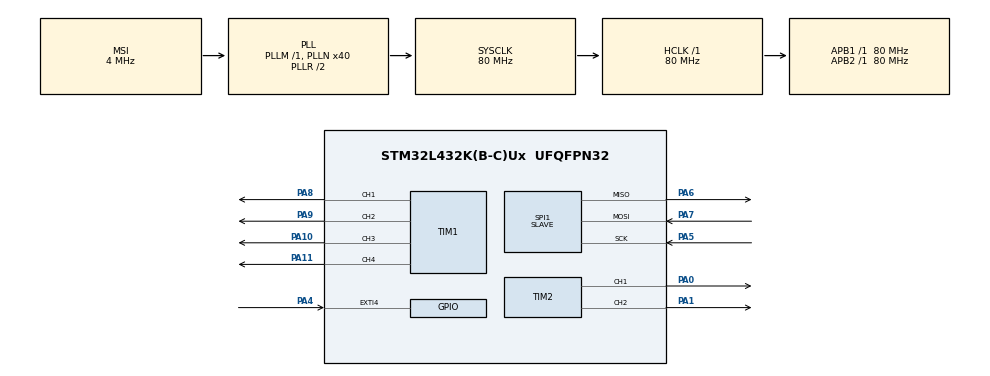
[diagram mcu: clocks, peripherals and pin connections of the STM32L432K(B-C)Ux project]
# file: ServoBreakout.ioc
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Dma.Request0=SPI1_RX
Dma.Request1=SPI1_TX
Dma.SPI1_RX.0.Direction=DMA_PERIPH_TO_MEMORY
Dma.SPI1_RX.0.Instance=DMA1_Channel2
Dma.SPI1_RX.0.MemDataAlignment=DMA_MDATAALIGN_BYTE
Dma.SPI1_RX.0.MemInc=DMA_MINC_ENABLE
Dma.SPI1_RX.0.Mode=DMA_NORMAL
Dma.SPI1_RX.0.PeriphDataAlignment=DMA_PDATAALIGN_BYTE
Dma.SPI1_RX.0.PeriphInc=DMA_PINC_DISABLE
Dma.SPI1_RX.0.Priority=DMA_PRIORITY_LOW
Dma.SPI1_TX.1.Direction=DMA_MEMORY_TO_PERIPH
Dma.SPI1_TX.1.Instance=DMA1_Channel3
Dma.SPI1_TX.1.MemDataAlignment=DMA_MDATAALIGN_BYTE
Dma.SPI1_TX.1.MemInc=DMA_MINC_ENABLE
Dma.SPI1_TX.1.Mode=DMA_NORMAL
Dma.SPI1_TX.1.PeriphDataAlignment=DMA_PDATAALIGN_BYTE
Dma.SPI1_TX.1.PeriphInc=DMA_PINC_DISABLE
Dma.SPI1_TX.1.Priority=DMA_PRIORITY_LOW
Mcu.Family=STM32L4
Mcu.Name=STM32L432K(B-C)Ux
Mcu.Package=UFQFPN32
NVIC.DMA1_Channel2_IRQn=true\:0\:0\:false\:true\:true\:1\:false
NVIC.DMA1_Channel3_IRQn=true\:0\:0\:false\:true\:true\:2\:false
NVIC.EXTI4_IRQn=true\:0\:0\:false\:false\:true\:true
NVIC.PriorityGroup=NVIC_PRIORITYGROUP_4
PA0.GPIO_Speed=GPIO_SPEED_FREQ_VERY_HIGH
PA0.Signal=S_TIM2_CH1
PA1.GPIO_Speed=GPIO_SPEED_FREQ_VERY_HIGH
PA1.Signal=S_TIM2_CH2
PA10.GPIO_Speed=GPIO_SPEED_FREQ_VERY_HIGH
PA10.Signal=S_TIM1_CH3
PA11.GPIO_Speed=GPIO_SPEED_FREQ_VERY_HIGH
PA11.Signal=S_TIM1_CH4
PA4.GPIO_PuPd=GPIO_PULLDOWN
PA4.Signal=GPXTI4
PA5.Mode=Full_Duplex_Slave
PA5.Signal=SPI1_SCK
PA6.Mode=Full_Duplex_Slave
PA6.Signal=SPI1_MISO
PA7.Mode=Full_Duplex_Slave
PA7.Signal=SPI1_MOSI
PA8.GPIO_Speed=GPIO_SPEED_FREQ_VERY_HIGH
PA8.Signal=S_TIM1_CH1
PA9.GPIO_Speed=GPIO_SPEED_FREQ_VERY_HIGH
PA9.Signal=S_TIM1_CH2
ProjectManager.HeapSize=0x200
ProjectManager.StackSize=0x400
ProjectManager.TargetToolchain=SW4STM32
RCC.AHBFreq_Value=80000000
RCC.APB1Freq_Value=80000000
RCC.APB1TimFreq_Value=80000000
RCC.APB2Freq_Value=80000000
RCC.APB2TimFreq_Value=80000000
RCC.CortexFreq_Value=80000000
RCC.HCLKFreq_Value=80000000
RCC.HSE_VALUE=8000000
RCC.HSI48_VALUE=48000000
RCC.HSI_VALUE=16000000
RCC.LSE_VALUE=32768
RCC.MSI_VALUE=4000000
RCC.PLLN=40
RCC.SYSCLKFreq_VALUE=80000000
RCC.SYSCLKSource=RCC_SYSCLKSOURCE_PLLCLK
RCC.VCOOutputFreq_Value=160000000
SH.S_TIM1_CH1.0=TIM1_CH1,PWM Generation1 CH1
SH.S_TIM1_CH2.0=TIM1_CH2,PWM Generation2 CH2
SH.S_TIM1_CH3.0=TIM1_CH3,PWM Generation3 CH3
SH.S_TIM1_CH4.0=TIM1_CH4,PWM Generation4 CH4
SH.S_TIM2_CH1.0=TIM2_CH1,PWM Generation1 CH1
SH.S_TIM2_CH2.0=TIM2_CH2,PWM Generation2 CH2
SPI1.Direction=SPI_DIRECTION_2LINES
SPI1.Mode=SPI_MODE_SLAVE
SPI1.VirtualType=VM_SLAVE
TIM1.Channel-PWM\ Generation1\ CH1=TIM_CHANNEL_1
TIM1.Channel-PWM\ Generation2\ CH2=TIM_CHANNEL_2
TIM1.Channel-PWM\ Generation3\ CH3=TIM_CHANNEL_3
TIM1.Channel-PWM\ Generation4\ CH4=TIM_CHANNEL_4
TIM2.Channel-PWM\ Generation1\ CH1=TIM_CHANNEL_1
TIM2.Channel-PWM\ Generation2\ CH2=TIM_CHANNEL_2
board=custom

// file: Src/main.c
/**
 ******************************************************************************
 * @file           : main.c
 * @brief          : Main program body
 ******************************************************************************
 ** This notice applies to any and all portions of this file
 * that are not between comment pairs USER CODE BEGIN and
 * USER CODE END. Other portions of this file, whether
 * inserted by the user or by software development tools
 * are owned by their respective copyright owners.
 *
 * COPYRIGHT(c) 2019 STMicroelectronics
 *
 * Redistribution and use in source and binary forms, with or without modification,
 * are permitted provided that the following conditions are met:
 *   1. Redistributions of source code must retain the above copyright notice,
 *      this list of conditions and the following disclaimer.
 *   2. Redistributions in binary form must reproduce the above copyright notice,
 *      this list of conditions and the following disclaimer in the documentation
 *      and/or other materials provided with the distribution.
 *   3. Neither the name of STMicroelectronics nor the names of its contributors
 *      may be used to endorse or promote products derived from this software
 *      without specific prior written permission.
 *
 * THIS SOFTWARE IS PROVIDED BY THE COPYRIGHT HOLDERS AND CONTRIBUTORS "AS IS"
 * AND ANY EXPRESS OR IMPLIED WARRANTIES, INCLUDING, BUT NOT LIMITED TO, THE
 * IMPLIED WARRANTIES OF MERCHANTABILITY AND FITNESS FOR A PARTICULAR PURPOSE ARE
 * DISCLAIMED. IN NO EVENT SHALL THE COPYRIGHT HOLDER OR CONTRIBUTORS BE LIABLE
 * FOR ANY DIRECT, INDIRECT, INCIDENTAL, SPECIAL, EXEMPLARY, OR CONSEQUENTIAL
 * DAMAGES (INCLUDING, BUT NOT LIMITED TO, PROCUREMENT OF SUBSTITUTE GOODS OR
 * SERVICES; LOSS OF USE, DATA, OR PROFITS; OR BUSINESS INTERRUPTION) HOWEVER
 * CAUSED AND ON ANY THEORY OF LIABILITY, WHETHER IN CONTRACT, STRICT LIABILITY,
 * OR TORT (INCLUDING NEGLIGENCE OR OTHERWISE) ARISING IN ANY WAY OUT OF THE USE
 * OF THIS SOFTWARE, EVEN IF ADVISED OF THE POSSIBILITY OF SUCH DAMAGE.
 *
 ******************************************************************************
 */
#include "main.h"
#include "stm32l4xx_hal.h"

SPI_HandleTypeDef hspi1;
DMA_HandleTypeDef hdma_spi1_rx;
DMA_HandleTypeDef hdma_spi1_tx;

TIM_HandleTypeDef htim1;
TIM_HandleTypeDef htim2;
#define PWM_Period 800
uint8_t DevID;

/* USER CODE BEGIN PV */
/* Private variables ---------------------------------------------------------*/

/* USER CODE END PV */

void SystemClock_Config(void);
static void MX_GPIO_Init(void);
static void MX_DMA_Init(void);
static void MX_TIM1_Init(void);
static void MX_TIM2_Init(void);
static void MX_SPI1_Init(void);
static void MX_NVIC_Init(void);

void HAL_TIM_MspPostInit(TIM_HandleTypeDef *htim);

int PCLK1_Freq = HAL_RCC_GetPCLK2Freq();

/* USER CODE BEGIN PFP */
/* Private function prototypes -----------------------------------------------*/

/* USER CODE END PFP */

int main(void)
{

	/* MCU Configuration----------------------------------------------------------*/

	/* Reset of all peripherals, Initializes the Flash interface and the Systick. */
	HAL_Init();

	/* Configure the system clock */
	SystemClock_Config();

	/* Initialize all configured peripherals */
	MX_GPIO_Init();
	MX_DMA_Init();
	MX_TIM1_Init();
	MX_TIM2_Init();
	MX_SPI1_Init();

	/* Initialize interrupts */
	MX_NVIC_Init();
	/* USER CODE BEGIN 2 */
	__HAL_TIM_SET_AUTORELOAD(&htim2, PCLK1_Freq / PWM_Period);
	__HAL_TIM_SET_AUTORELOAD(&htim1, PCLK1_Freq / PWM_Period);

	/* USER CODE END 2 */

	/* Infinite loop */
	while (1)
	{

	}

}

void SystemClock_Config(void)
{

	RCC_OscInitTypeDef RCC_OscInitStruct;
	RCC_ClkInitTypeDef RCC_ClkInitStruct;

	/**Initializes the CPU, AHB and APB busses clocks
	 */
	RCC_OscInitStruct.OscillatorType = RCC_OSCILLATORTYPE_MSI;
	RCC_OscInitStruct.MSIState = RCC_MSI_ON;
	RCC_OscInitStruct.MSICalibrationValue = 0;
	RCC_OscInitStruct.MSIClockRange = RCC_MSIRANGE_6;
	RCC_OscInitStruct.PLL.PLLState = RCC_PLL_ON;
	RCC_OscInitStruct.PLL.PLLSource = RCC_PLLSOURCE_MSI;
	RCC_OscInitStruct.PLL.PLLM = 1;
	RCC_OscInitStruct.PLL.PLLN = 40;
	RCC_OscInitStruct.PLL.PLLP = RCC_PLLP_DIV7;
	RCC_OscInitStruct.PLL.PLLQ = RCC_PLLQ_DIV2;
	RCC_OscInitStruct.PLL.PLLR = RCC_PLLR_DIV2;
	if (HAL_RCC_OscConfig(&RCC_OscInitStruct) != HAL_OK)
	{
		_Error_Handler(__FILE__, __LINE__);
	}

	/**Initializes the CPU, AHB and APB busses clocks
	 */
	RCC_ClkInitStruct.ClockType = RCC_CLOCKTYPE_HCLK|RCC_CLOCKTYPE_SYSCLK
			|RCC_CLOCKTYPE_PCLK1|RCC_CLOCKTYPE_PCLK2;
	RCC_ClkInitStruct.SYSCLKSource = RCC_SYSCLKSOURCE_PLLCLK;
	RCC_ClkInitStruct.AHBCLKDivider = RCC_SYSCLK_DIV1;
	RCC_ClkInitStruct.APB1CLKDivider = RCC_HCLK_DIV1;
	RCC_ClkInitStruct.APB2CLKDivider = RCC_HCLK_DIV1;

	if (HAL_RCC_ClockConfig(&RCC_ClkInitStruct, FLASH_LATENCY_4) != HAL_OK)
	{
		_Error_Handler(__FILE__, __LINE__);
	}

	/**Configure the main internal regulator output voltage
	 */
	if (HAL_PWREx_ControlVoltageScaling(PWR_REGULATOR_VOLTAGE_SCALE1) != HAL_OK)
	{
		_Error_Handler(__FILE__, __LINE__);
	}

	/**Configure the Systick interrupt time
	 */
	HAL_SYSTICK_Config(HAL_RCC_GetHCLKFreq()/1000);

	/**Configure the Systick
	 */
	HAL_SYSTICK_CLKSourceConfig(SYSTICK_CLKSOURCE_HCLK);

	/* SysTick_IRQn interrupt configuration */
	HAL_NVIC_SetPriority(SysTick_IRQn, 0, 0);
}

/**
 * @brief NVIC Configuration.
 * @retval None
 */
static void MX_NVIC_Init(void)
{
	/* DMA1_Channel2_IRQn interrupt configuration */
	HAL_NVIC_SetPriority(DMA1_Channel2_IRQn, 0, 0);
	HAL_NVIC_EnableIRQ(DMA1_Channel2_IRQn);
	/* DMA1_Channel3_IRQn interrupt configuration */
	HAL_NVIC_SetPriority(DMA1_Channel3_IRQn, 0, 0);
	HAL_NVIC_EnableIRQ(DMA1_Channel3_IRQn);
}

/* SPI1 init function */
static void MX_SPI1_Init(void)
{

	/* SPI1 parameter configuration*/
	hspi1.Instance = SPI1;
	hspi1.Init.Mode = SPI_MODE_SLAVE;
	hspi1.Init.Direction = SPI_DIRECTION_2LINES;
	hspi1.Init.DataSize = SPI_DATASIZE_4BIT;
	hspi1.Init.CLKPolarity = SPI_POLARITY_LOW;
	hspi1.Init.CLKPhase = SPI_PHASE_1EDGE;
	hspi1.Init.NSS = SPI_NSS_SOFT;
	hspi1.Init.FirstBit = SPI_FIRSTBIT_MSB;
	hspi1.Init.TIMode = SPI_TIMODE_DISABLE;
	hspi1.Init.CRCCalculation = SPI_CRCCALCULATION_DISABLE;
	hspi1.Init.CRCPolynomial = 7;
	hspi1.Init.CRCLength = SPI_CRC_LENGTH_DATASIZE;
	hspi1.Init.NSSPMode = SPI_NSS_PULSE_DISABLE;
	if (HAL_SPI_Init(&hspi1) != HAL_OK)
	{
		_Error_Handler(__FILE__, __LINE__);
	}

}

/* TIM1 init function */
static void MX_TIM1_Init(void)
{

	TIM_MasterConfigTypeDef sMasterConfig;
	TIM_OC_InitTypeDef sConfigOC;
	TIM_BreakDeadTimeConfigTypeDef sBreakDeadTimeConfig;

	htim1.Instance = TIM1;
	htim1.Init.Prescaler = 0;
	htim1.Init.CounterMode = TIM_COUNTERMODE_UP;
	htim1.Init.Period = 0;
	htim1.Init.ClockDivision = TIM_CLOCKDIVISION_DIV1;
	htim1.Init.RepetitionCounter = 0;
	htim1.Init.AutoReloadPreload = TIM_AUTORELOAD_PRELOAD_DISABLE;
	if (HAL_TIM_PWM_Init(&htim1) != HAL_OK)
	{
		_Error_Handler(__FILE__, __LINE__);
	}

	sMasterConfig.MasterOutputTrigger = TIM_TRGO_RESET;
	sMasterConfig.MasterOutputTrigger2 = TIM_TRGO2_RESET;
	sMasterConfig.MasterSlaveMode = TIM_MASTERSLAVEMODE_DISABLE;
	if (HAL_TIMEx_MasterConfigSynchronization(&htim1, &sMasterConfig) != HAL_OK)
	{
		_Error_Handler(__FILE__, __LINE__);
	}

	sConfigOC.OCMode = TIM_OCMODE_PWM1;
	sConfigOC.Pulse = 0;
	sConfigOC.OCPolarity = TIM_OCPOLARITY_HIGH;
	sConfigOC.OCNPolarity = TIM_OCNPOLARITY_HIGH;
	sConfigOC.OCFastMode = TIM_OCFAST_DISABLE;
	sConfigOC.OCIdleState = TIM_OCIDLESTATE_RESET;
	sConfigOC.OCNIdleState = TIM_OCNIDLESTATE_RESET;
	if (HAL_TIM_PWM_ConfigChannel(&htim1, &sConfigOC, TIM_CHANNEL_1) != HAL_OK)
	{
		_Error_Handler(__FILE__, __LINE__);
	}

	if (HAL_TIM_PWM_ConfigChannel(&htim1, &sConfigOC, TIM_CHANNEL_2) != HAL_OK)
	{
		_Error_Handler(__FILE__, __LINE__);
	}

	if (HAL_TIM_PWM_ConfigChannel(&htim1, &sConfigOC, TIM_CHANNEL_3) != HAL_OK)
	{
		_Error_Handler(__FILE__, __LINE__);
	}

	if (HAL_TIM_PWM_ConfigChannel(&htim1, &sConfigOC, TIM_CHANNEL_4) != HAL_OK)
	{
		_Error_Handler(__FILE__, __LINE__);
	}

	sBreakDeadTimeConfig.OffStateRunMode = TIM_OSSR_DISABLE;
	sBreakDeadTimeConfig.OffStateIDLEMode = TIM_OSSI_DISABLE;
	sBreakDeadTimeConfig.LockLevel = TIM_LOCKLEVEL_OFF;
	sBreakDeadTimeConfig.DeadTime = 0;
	sBreakDeadTimeConfig.BreakState = TIM_BREAK_DISABLE;
	sBreakDeadTimeConfig.BreakPolarity = TIM_BREAKPOLARITY_HIGH;
	sBreakDeadTimeConfig.BreakFilter = 0;
	sBreakDeadTimeConfig.Break2State = TIM_BREAK2_DISABLE;
	sBreakDeadTimeConfig.Break2Polarity = TIM_BREAK2POLARITY_HIGH;
	sBreakDeadTimeConfig.Break2Filter = 0;
	sBreakDeadTimeConfig.AutomaticOutput = TIM_AUTOMATICOUTPUT_DISABLE;
	if (HAL_TIMEx_ConfigBreakDeadTime(&htim1, &sBreakDeadTimeConfig) != HAL_OK)
	{
		_Error_Handler(__FILE__, __LINE__);
	}

	HAL_TIM_MspPostInit(&htim1);

}

/* TIM2 init function */
static void MX_TIM2_Init(void)
{

	TIM_MasterConfigTypeDef sMasterConfig;
	TIM_OC_InitTypeDef sConfigOC;

	htim2.Instance = TIM2;
	htim2.Init.Prescaler = 0;
	htim2.Init.CounterMode = TIM_COUNTERMODE_UP;
	htim2.Init.Period = 0;
	htim2.Init.ClockDivision = TIM_CLOCKDIVISION_DIV1;
	htim2.Init.AutoReloadPreload = TIM_AUTORELOAD_PRELOAD_DISABLE;
	if (HAL_TIM_PWM_Init(&htim2) != HAL_OK)
	{
		_Error_Handler(__FILE__, __LINE__);
	}

	sMasterConfig.MasterOutputTrigger = TIM_TRGO_RESET;
	sMasterConfig.MasterSlaveMode = TIM_MASTERSLAVEMODE_DISABLE;
	if (HAL_TIMEx_MasterConfigSynchronization(&htim2, &sMasterConfig) != HAL_OK)
	{
		_Error_Handler(__FILE__, __LINE__);
	}

	sConfigOC.OCMode = TIM_OCMODE_PWM1;
	sConfigOC.Pulse = 0;
	sConfigOC.OCPolarity = TIM_OCPOLARITY_HIGH;
	sConfigOC.OCFastMode = TIM_OCFAST_DISABLE;
	if (HAL_TIM_PWM_ConfigChannel(&htim2, &sConfigOC, TIM_CHANNEL_1) != HAL_OK)
	{
		_Error_Handler(__FILE__, __LINE__);
	}

	if (HAL_TIM_PWM_ConfigChannel(&htim2, &sConfigOC, TIM_CHANNEL_2) != HAL_OK)
	{
		_Error_Handler(__FILE__, __LINE__);
	}

	HAL_TIM_MspPostInit(&htim2);

}

static void MX_DMA_Init(void)
{
	/* DMA controller clock enable */
	__HAL_RCC_DMA1_CLK_ENABLE();

}

/** Configure pins as
 * Analog
 * Input
 * Output
 * EVENT_OUT
 * EXTI
 */
static void MX_GPIO_Init(void)
{

	GPIO_InitTypeDef GPIO_InitStruct;

	/* GPIO Ports Clock Enable */
	__HAL_RCC_GPIOA_CLK_ENABLE();

	/*Configure GPIO pin : PA4 */
	GPIO_InitStruct.Pin = GPIO_PIN_4;
	GPIO_InitStruct.Mode = GPIO_MODE_IT_RISING;
	GPIO_InitStruct.Pull = GPIO_PULLDOWN;
	HAL_GPIO_Init(GPIOA, &GPIO_InitStruct);

	/* EXTI interrupt init*/
	HAL_NVIC_SetPriority(EXTI4_IRQn, 0, 0);
	HAL_NVIC_EnableIRQ(EXTI4_IRQn);

}

void _Error_Handler(char *file, int line)
{
	while(1)
	{
	}
}

/************************ (C) COPYRIGHT STMicroelectronics *****END OF FILE****/
